# STM32F40x register map
File version: 1.5
Registers are 32-bit, read-write, reset 0x0 unless marked. A register's access mark holds for its fields unless they carry their own. Offsets are from the block's base; [hi:lo] are bit positions; {n}, {i} and the like mark numbered series.

## FLASH（闪存） — 片内 Flash：编程/擦除/读保护 | FLASH
Base 0x40023C00
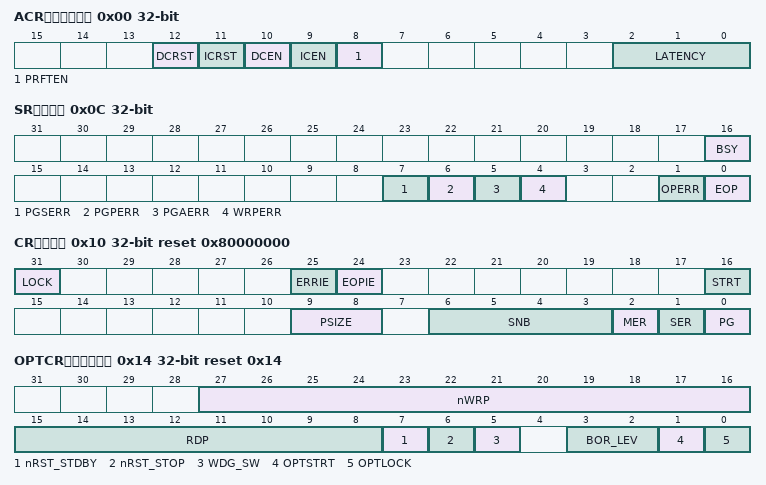
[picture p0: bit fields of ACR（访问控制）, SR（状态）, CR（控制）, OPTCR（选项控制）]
0x00 ACR（访问控制） access per field — 访问控制：等待周期/预取/缓存 | Flash access control register
  [12] DCRST rw — Data cache reset
  [11] ICRST wo — Instruction cache reset
  [10] DCEN rw — Data cache enable
  [9] ICEN rw — Instruction cache enable
  [8] PRFTEN rw — Prefetch enable
  [2:0] LATENCY rw
0x04 KEYR（密钥） wo — 解锁 FLASH 编程密钥 | Flash key register
  [31:0] KEY — FPEC key
0x08 OPTKEYR（选项密钥） wo — 解锁选项字节密钥 | Flash option key register
  [31:0] OPTKEY — Option byte key
0x0C SR（状态） access per field — 状态：忙/错误 等编程状态 | Status register
  [16] BSY ro — Busy
  [7] PGSERR rw — Programming sequence error
  [6] PGPERR rw — Programming parallelism error
  [5] PGAERR rw — Programming alignment error
  [4] WRPERR rw — Write protection error
  [1] OPERR rw — Operation error
  [0] EOP rw — End of operation
0x10 CR（控制） reset 0x80000000 — 控制：编程/擦除/锁定/选项编程 | Control register
  [31] LOCK
  [25] ERRIE — Error interrupt enable
  [24] EOPIE — End of operation interrupt enable
  [16] STRT — Start
  [9:8] PSIZE — Program size
  [6:3] SNB — Sector number
  [2] MER — Mass Erase
  [1] SER — Sector Erase
  [0] PG — Programming
0x14 OPTCR（选项控制） reset 0x14 — 选项控制：读保护/看门狗/复位选择 | Flash option control register
  [27:16] nWRP — Not write protect
  [15:8] RDP — Read protect
  [7] nRST_STDBY — nRST_STDBY User option bytes
  [6] nRST_STOP — nRST_STOP User option bytes
  [5] WDG_SW — WDG_SW User option bytes
  [3:2] BOR_LEV — BOR reset Level
  [1] OPTSTRT — Option start
  [0] OPTLOCK — Option lock

## EXTI（外部中断） — 外部中断/事件控制器：GPIO 等外部信号触发 | External interrupt/event controller
Base 0x40013C00
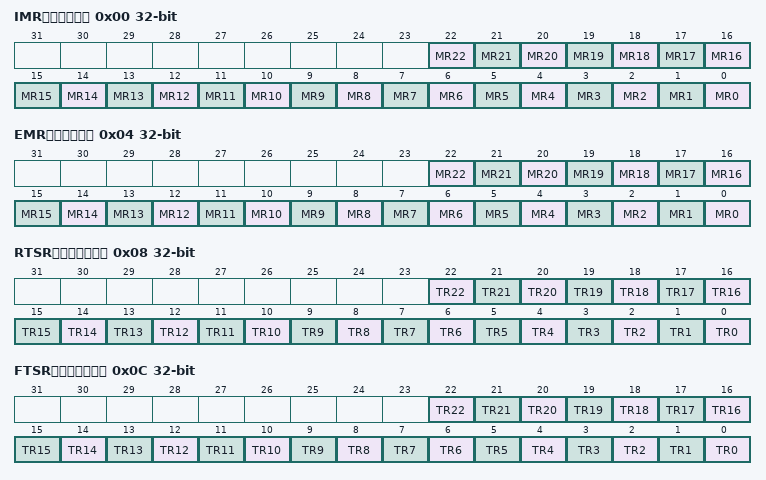
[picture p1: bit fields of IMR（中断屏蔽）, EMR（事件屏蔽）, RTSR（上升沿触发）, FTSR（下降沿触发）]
0x00 IMR（中断屏蔽） — 中断屏蔽：允许/禁止各中断线 | Interrupt mask register (EXTI_IMR)
  [n] MR{n} (n=0..22) — Interrupt Mask on line {n}
0x04 EMR（事件屏蔽） — 事件屏蔽：允许/禁止各事件线 | Event mask register (EXTI_EMR)
  [n] MR{n} (n=0..22) — Event Mask on line {n}
0x08 RTSR（上升沿触发） — 上升沿触发选择 | Rising Trigger selection register (EXTI_RTSR)
  [n] TR{n} (n=0..22) — Rising trigger event configuration of line {n}
0x0C FTSR（下降沿触发） — 下降沿触发选择 | Falling Trigger selection register (EXTI_FTSR)
  [n] TR{n} (n=0..22) — Falling trigger event configuration of line {n}
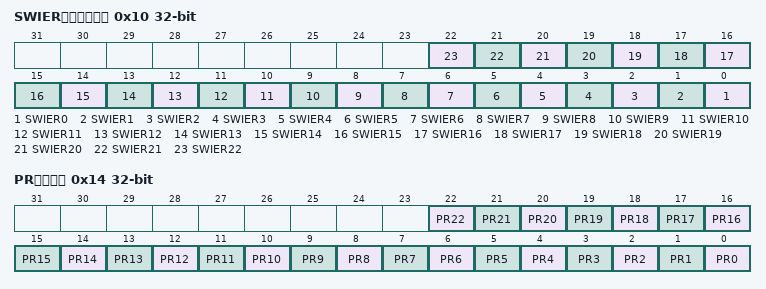
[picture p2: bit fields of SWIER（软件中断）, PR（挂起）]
0x10 SWIER（软件中断） — 软件触发中断 | Software interrupt event register (EXTI_SWIER)
  [n] SWIER{n} (n=0..22) — Software Interrupt on line {n}
0x14 PR（挂起） — 中断挂起标志（写1清） | Pending register (EXTI_PR)
  [n] PR{n} (n=0..22) — Pending bit {n}

## OTG_HS_PWRCLK（USB_OTG_HS_电源时钟寄存器） — USB OTG HS 电源时钟寄存器（best-effort） | USB on the go high speed
Base 0x40040E00
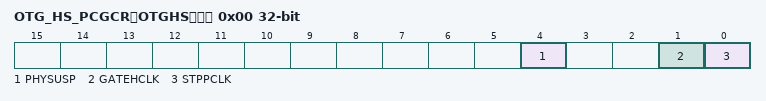
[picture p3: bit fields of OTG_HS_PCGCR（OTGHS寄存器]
0x00 OTG_HS_PCGCR（OTGHS寄存器 PCGCR） — USB OTG HS 寄存器 PCGCR（best-effort） | Power and clock gating control register
  [4] PHYSUSP — PHY suspended
  [1] GATEHCLK
  [0] STPPCLK — Stop PHY clock

## NVIC（中断控制器） — 嵌套向量中断控制器：中断使能与优先级 | Nested Vectored Interrupt Controller
Base 0xE000E000
0x04 ICTR（中断数） ro — 中断控制器类型 | Interrupt Controller Type Register
  [3:0] INTLINESNUM — Total number of interrupt lines in groups
{0x100+4i} ISER{i}（中断使能{i}） (i=0..2) — 中断 set-enable {i} | Interrupt Set-Enable Register
  [31:0] SETENA
{0x180+4i} ICER{i}（中断禁能{i}） (i=0..2) — 中断 clear-enable {i} | Interrupt Clear-Enable Register
  [31:0] CLRENA
{0x200+4i} ISPR{i}（中断挂起{i}） (i=0..2) — 中断 set-pending {i} | Interrupt Set-Pending Register
  [31:0] SETPEND
{0x280+4i} ICPR{i}（中断清挂起{i}） (i=0..2) — 中断 clear-pending {i} | Interrupt Clear-Pending Register
  [31:0] CLRPEND
{0x300+4i} IABR{i}（中断活跃{i}） ro (i=0..2) — 中断 active 状态（只读）{i} | Interrupt Active Bit Register
  [31:0] ACTIVE
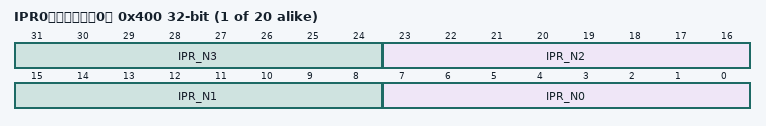
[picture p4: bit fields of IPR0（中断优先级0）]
{0x400+4i} IPR{i}（中断优先级{i}） (i=0..19) — 中断优先级寄存器 {i}（0~255） | Interrupt Priority Register
  [8n+7:8n] IPR_N{n} (n=0..3)
0xF00 STIR（软件触发） wo — 软件触发中断寄存器 | Software Triggered Interrupt Register
  [8:0] INTID — interrupt to be triggered
